VERSION ""

NS_ :

BS_:

BU_: VCU ACU
VAL_TABLE_ AutoCleanSta 1 "On" 0 "Off" ;
VAL_TABLE_ FanSpeedMode 1 "Speed" 0 "Default" ;
VAL_TABLE_ FanModeCtrl 3 "High" 2 "Mid" 1 "Low" 0 "Off" ;
VAL_TABLE_ DedustingCtrl 1 "On" 0 "Off" ;
VAL_TABLE_ ShakerDuster 1 "On" 0 "Off" ;
VAL_TABLE_ SweepUpDwonCtrl 2 "Down" 1 "Up" 0 "No" ;
VAL_TABLE_ MouthpieceUpDownCtrl 2 "Down" 1 "Up" 0 "No" ;
VAL_TABLE_ StartStop 3 "No" 2 "Stop" 1 "Start" 0 "No" ;
VAL_TABLE_ MowingSpeedModeCtrl 3 "High" 2 "Mid" 1 "Low" 0 "Off" ;
VAL_TABLE_ MowingSpeedMode 3 "High" 2 "Mid" 1 "Low" 0 "Off" ;
VAL_TABLE_ SweepModeFb 3 "High" 2 "Mid" 1 "Low" 0 "Off" ;
VAL_TABLE_ SweepModeCtrl 3 "High" 2 "Mid" 1 "Low" 0 "Off" ;
VAL_TABLE_ CarWorkStaFb 7 "crash" 6 "error" 5 "E-stop" 4 "work" 3 "3" 2 "2" 1 "1" 0 "init" ;
VAL_TABLE_ AutoProfessional 1 "Enable" 0 "Disable" ;
VAL_TABLE_ CarWork_State 3 "FAULT" 2 "OK" 1 "SELF_CHECK" 0 "INIT" ;
VAL_TABLE_ CarPower_State 2 "READY" 1 "ON" 0 "OFF" ;
VAL_TABLE_ Headlight 1 "On" 0 "Off" ;
VAL_TABLE_ AEB_Trigger_State 8 "RightTrigger" 4 "LeftTrigger" 2 "BackTrigger" 1 "FrontTrigger" 0 "NoTrigger" ;
VAL_TABLE_ Brake_Light_Actual 1 "BrakeLight_ON" 0 "BrakeLight_OFF" ;
VAL_TABLE_ Turn_Light_Actual 3 "Hazard_Warning_Lampsts_ON" 2 "Right_Turnlampsts_ON" 1 "Left_Turnlampsts_ON" 0 "Turnlampsts_OFF" ;
VAL_TABLE_ VIN_Req 1 "Vin_req_enable" 0 "Vin_req_disable" ;
VAL_TABLE_ Drive_Mode_STS 1 "Speed Drive Mode" 0 "Throttle Paddle Drive Mode" ;
VAL_TABLE_ Steer_Mode_STS 2 "Sync Direction Steer Mode" 1 "Non Direction Steer Mode" 0 "Standard Steer Mode" ;
VAL_TABLE_ Steer_Mode_CTRL 2 "Sync Direction Steer" 1 "Non Direction Steer" 0 "Standard Steer" ;
VAL_TABLE_ Drive_Mode_CTRL 1 "Speed Drive" 0 "Throttle Paddle Drive" ;
VAL_TABLE_ AEB_EN_CTRL 1 "Enable AEB" 0 "Disable AEB" ;
VAL_TABLE_ Vehicle_Mode_State 3 "Standby Mode" 2 "Emergency Mode" 1 "Auto Mode" 0 "Manual Remote  Mode" ;
VAL_TABLE_ BackCrash_State 1 "Crash Event" 0 "No Event" ;
VAL_TABLE_ FrontCrash_State 1 "Crash Event" 0 "No Event" ;
VAL_TABLE_ AEB_State 1 "Active" 0 "Inctive" ;
VAL_TABLE_ Brake_FLT2 1 "Brake system comunication fault" 0 "No fault " ;
VAL_TABLE_ Brake_FLT1 1 "Brake system hardware fault" 0 "No fault" ;
VAL_TABLE_ Brake_EN_CTRL 1 "Enable" 0 "Disable" ;
VAL_TABLE_ Brake_EN_state 3 "Standby" 2 "Takeover" 1 "Auto" 0 "Manual" ;
VAL_TABLE_ Park_FLT 1 "Fault" 0 "No Fault" ;
VAL_TABLE_ Parking_actual 1 "Parking_trigger" 0 "Release" ;
VAL_TABLE_ Park_Target 1 "Parking_trigger" 0 "Release" ;
VAL_TABLE_ Park_EN_CTRL 1 "Enable" 0 "Disable" ;
VAL_TABLE_ Gear_FLT 1 "Fault" 0 "No Fault" ;
VAL_TABLE_ Gear_Actual 4 "D" 3 "N" 2 "R" 1 "P" 0 "Invaild" ;
VAL_TABLE_ Gear_Target 4 "D" 3 "N" 2 "R" 1 "P" 0 "Invalid" ;
VAL_TABLE_ Gear_EN_CTRL 1 "Enable" 0 "Disable" ;
VAL_TABLE_ Throttle_EN_state 3 "Standby" 2 "Takeover" 1 "Auto" 0 "Manual" ;
VAL_TABLE_ Throttle_EN_CTRL 1 "Enable" 0 "Disable" ;
VAL_TABLE_ Steer_EN_state 3 "Standby" 2 "Takeover" 1 "Auto" 0 "Manual" ;
VAL_TABLE_ Steer_EN_CTRL 1 "Enable" 0 "Disable" ;
VAL_TABLE_ Throttle_FLT2 1 "Drive system comunication fault" 0 "No fault" ;
VAL_TABLE_ Throttle_FLT1 1 "Drive system hardware fault" 0 "No fault" ;
VAL_TABLE_ Steer_FLT2 1 "Steer system comunication fault" 0 "No fault" ;
VAL_TABLE_ Steer_FLT1 1 "Steer system hardware fault" 0 "No fault" ;

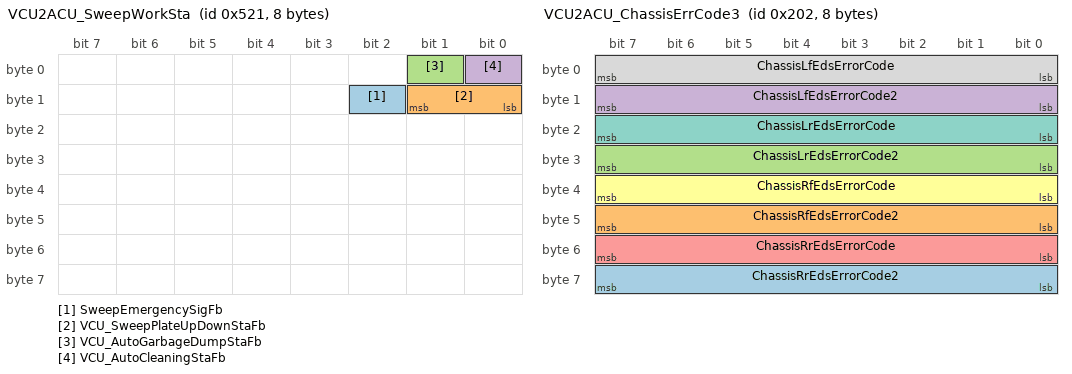
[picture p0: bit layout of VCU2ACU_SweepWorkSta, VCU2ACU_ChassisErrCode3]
BO_ 1313 VCU2ACU_SweepWorkSta: 8 VCU
 SG_ SweepEmergencySigFb : 10|1@0+ (1,0) [0|1] "" Vector__XXX
 SG_ VCU_SweepPlateUpDownStaFb : 9|2@0+ (1,0) [0|1] "" Vector__XXX
 SG_ VCU_AutoGarbageDumpStaFb : 1|1@0+ (1,0) [0|0] "" Vector__XXX
 SG_ VCU_AutoCleaningStaFb : 0|1@0+ (1,0) [0|0] "" Vector__XXX

BO_ 514 VCU2ACU_ChassisErrCode3: 8 VCU
 SG_ ChassisRrEdsErrorCode2 : 63|8@0+ (1,0) [0|0] "" Vector__XXX
 SG_ ChassisRfEdsErrorCode2 : 47|8@0+ (1,0) [0|0] "" Vector__XXX
 SG_ ChassisLrEdsErrorCode2 : 31|8@0+ (1,0) [0|0] "" Vector__XXX
 SG_ ChassisLfEdsErrorCode2 : 15|8@0+ (1,0) [0|0] "" Vector__XXX
 SG_ ChassisRrEdsErrorCode : 55|8@0+ (1,0) [0|0] "" Vector__XXX
 SG_ ChassisRfEdsErrorCode : 39|8@0+ (1,0) [0|0] "" Vector__XXX
 SG_ ChassisLrEdsErrorCode : 23|8@0+ (1,0) [0|0] "" Vector__XXX
 SG_ ChassisLfEdsErrorCode : 7|8@0+ (1,0) [0|0] "" Vector__XXX

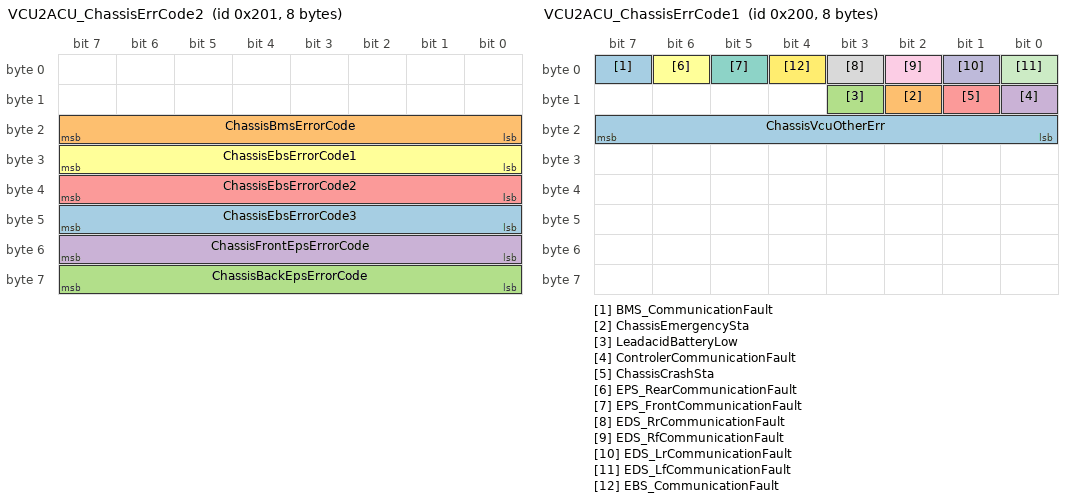
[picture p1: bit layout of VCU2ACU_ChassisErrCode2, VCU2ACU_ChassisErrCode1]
BO_ 513 VCU2ACU_ChassisErrCode2: 8 VCU
 SG_ ChassisEbsErrorCode3 : 47|8@0+ (1,0) [0|0] "" Vector__XXX
 SG_ ChassisBmsErrorCode : 23|8@0+ (1,0) [0|0] "" Vector__XXX
 SG_ ChassisBackEpsErrorCode : 63|8@0+ (1,0) [0|0] "" Vector__XXX
 SG_ ChassisFrontEpsErrorCode : 55|8@0+ (1,0) [0|0] "" Vector__XXX
 SG_ ChassisEbsErrorCode2 : 39|8@0+ (1,0) [0|0] "" Vector__XXX
 SG_ ChassisEbsErrorCode1 : 31|8@0+ (1,0) [0|0] "" Vector__XXX

BO_ 512 VCU2ACU_ChassisErrCode1: 8 VCU
 SG_ BMS_CommunicationFault : 7|1@0+ (1,0) [0|0] "" Vector__XXX
 SG_ ChassisEmergencySta : 10|1@0+ (1,0) [0|0] "" Vector__XXX
 SG_ LeadacidBatteryLow : 11|1@0+ (1,0) [0|0] "" Vector__XXX
 SG_ ControlerCommunicationFault : 8|1@0+ (1,0) [0|0] "" Vector__XXX
 SG_ ChassisCrashSta : 9|1@0+ (1,0) [0|0] "" Vector__XXX
 SG_ EPS_RearCommunicationFault : 6|1@0+ (1,0) [0|0] "" Vector__XXX
 SG_ EPS_FrontCommunicationFault : 5|1@0+ (1,0) [0|0] "" Vector__XXX
 SG_ EDS_RrCommunicationFault : 3|1@0+ (1,0) [0|0] "" Vector__XXX
 SG_ EDS_RfCommunicationFault : 2|1@0+ (1,0) [0|0] "" Vector__XXX
 SG_ EDS_LrCommunicationFault : 1|1@0+ (1,0) [0|0] "" Vector__XXX
 SG_ EDS_LfCommunicationFault : 0|1@0+ (1,0) [0|0] "" Vector__XXX
 SG_ EBS_CommunicationFault : 4|1@0+ (1,0) [0|0] "" Vector__XXX
 SG_ ChassisVcuOtherErr : 23|8@0+ (1,0) [0|0] "" Vector__XXX

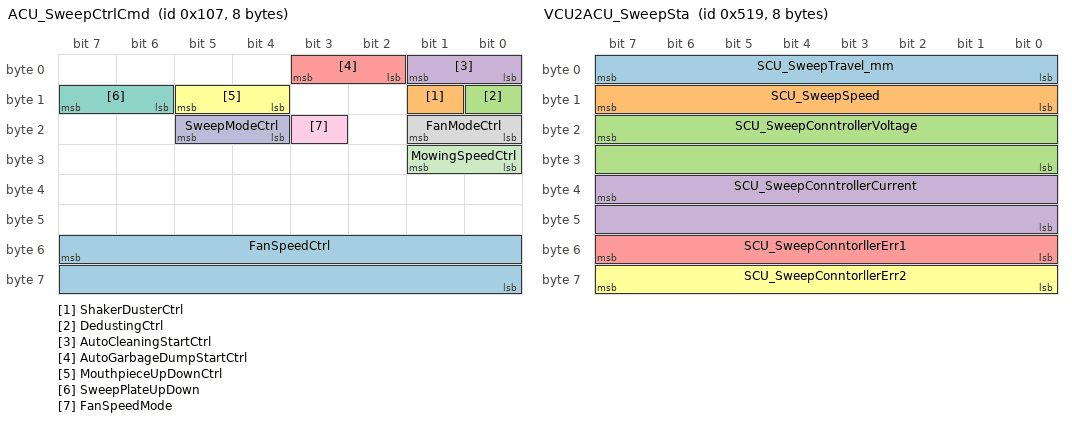
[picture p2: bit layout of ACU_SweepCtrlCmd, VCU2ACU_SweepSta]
BO_ 263 ACU_SweepCtrlCmd: 8 ACU
 SG_ FanSpeedCtrl : 55|16@0+ (1,0) [0|0] "rpm" Vector__XXX
 SG_ ShakerDusterCtrl : 9|1@0+ (1,0) [0|1] "" Vector__XXX
 SG_ DedustingCtrl : 8|1@0+ (1,0) [0|1] "" Vector__XXX
 SG_ AutoCleaningStartCtrl : 1|2@0+ (1,0) [0|3] "" Vector__XXX
 SG_ AutoGarbageDumpStartCtrl : 3|2@0+ (1,0) [0|3] "" Vector__XXX
 SG_ MouthpieceUpDownCtrl : 13|2@0+ (1,0) [0|3] "" Vector__XXX
 SG_ SweepPlateUpDown : 15|2@0+ (1,0) [0|3] "" Vector__XXX
 SG_ FanModeCtrl : 17|2@0+ (1,0) [0|3] "" Vector__XXX
 SG_ FanSpeedMode : 19|1@0+ (1,0) [0|1] "" Vector__XXX
 SG_ SweepModeCtrl : 21|2@0+ (1,0) [0|3] "" Vector__XXX
 SG_ MowingSpeedCtrl : 25|2@0+ (1,0) [0|3] "" Vector__XXX

BO_ 1312 VCU2ACU_SweepWeedingSta: 8 VCU
 SG_ SCU_WeedingSta : 7|8@0+ (1,0) [0|1] "" Vector__XXX

BO_ 1305 VCU2ACU_SweepSta: 8 VCU
 SG_ SCU_SweepTravel_mm : 7|8@0+ (1,0) [0|255] "mm" Vector__XXX
 SG_ SCU_SweepSpeed : 15|8@0+ (1,0) [0|255] "rpm" Vector__XXX
 SG_ SCU_SweepConntrollerVoltage : 23|16@0+ (1,0) [0|1] "" Vector__XXX
 SG_ SCU_SweepConntrollerCurrent : 39|16@0+ (1,0) [0|1] "" Vector__XXX
 SG_ SCU_SweepConntorllerErr1 : 55|8@0+ (1,0) [0|1] "" Vector__XXX
 SG_ SCU_SweepConntorllerErr2 : 63|8@0+ (1,0) [0|1] "" Vector__XXX

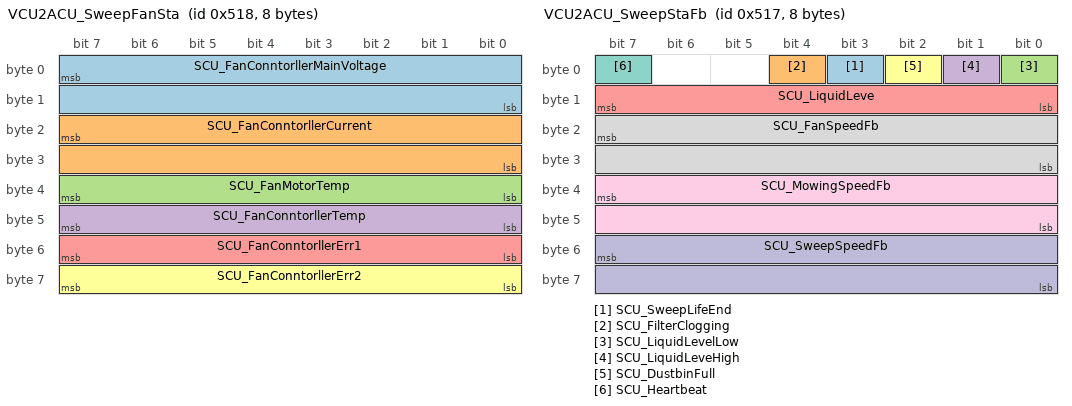
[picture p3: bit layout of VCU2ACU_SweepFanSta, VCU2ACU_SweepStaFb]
BO_ 1304 VCU2ACU_SweepFanSta: 8 VCU
 SG_ SCU_FanConntorllerMainVoltage : 7|16@0+ (1,0) [0|500] "V" Vector__XXX
 SG_ SCU_FanConntorllerCurrent : 23|16@0+ (1,-2000) [-2000|2000] "A" Vector__XXX
 SG_ SCU_FanMotorTemp : 39|8@0+ (1,-40) [-40|210] "℃" Vector__XXX
 SG_ SCU_FanConntorllerTemp : 47|8@0+ (1,-40) [-40|160] "℃" Vector__XXX
 SG_ SCU_FanConntorllerErr1 : 55|8@0+ (1,0) [0|1] "" Vector__XXX
 SG_ SCU_FanConntorllerErr2 : 63|8@0+ (1,0) [0|1] "" Vector__XXX

BO_ 1303 VCU2ACU_SweepStaFb: 8 VCU
 SG_ SCU_SweepLifeEnd : 3|1@0+ (1,0) [0|0] "" Vector__XXX
 SG_ SCU_FilterClogging : 4|1@0+ (1,0) [0|0] "" Vector__XXX
 SG_ SCU_LiquidLevelLow : 0|1@0+ (1,0) [0|1] "" Vector__XXX
 SG_ SCU_LiquidLeveHigh : 1|1@0+ (1,0) [0|1] "" Vector__XXX
 SG_ SCU_LiquidLeve : 15|8@0+ (1,0) [0|1] "" Vector__XXX
 SG_ SCU_DustbinFull : 2|1@0+ (1,0) [0|1] "" Vector__XXX
 SG_ SCU_Heartbeat : 7|1@0+ (1,0) [0|1] "" Vector__XXX
 SG_ SCU_FanSpeedFb : 23|16@0+ (1,0) [0|1] "" Vector__XXX
 SG_ SCU_MowingSpeedFb : 39|16@0+ (1,0) [0|1] "" Vector__XXX
 SG_ SCU_SweepSpeedFb : 55|16@0+ (1,0) [0|1] "" Vector__XXX

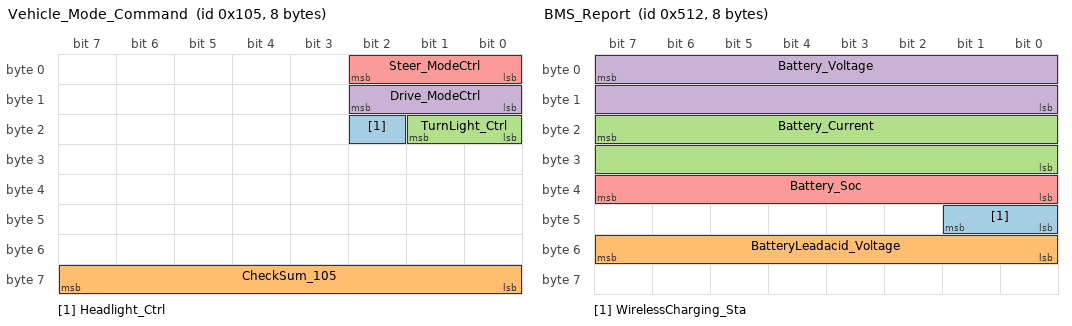
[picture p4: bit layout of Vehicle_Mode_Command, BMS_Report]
BO_ 261 Vehicle_Mode_Command: 8 ACU
 SG_ Headlight_Ctrl : 18|1@0+ (1,0) [0|0] "" Vector__XXX
 SG_ CheckSum_105 : 63|8@0+ (1,0) [0|255] "" Vector__XXX
 SG_ TurnLight_Ctrl : 17|2@0+ (1,0) [0|7] "" Vector__XXX
 SG_ Drive_ModeCtrl : 10|3@0+ (1,0) [0|7] "" Vector__XXX
 SG_ Steer_ModeCtrl : 2|3@0+ (1,0) [0|7] "" Vector__XXX

BO_ 1298 BMS_Report: 8 VCU
 SG_ WirelessCharging_Sta : 41|2@0+ (1,0) [0|0] "" Vector__XXX
 SG_ BatteryLeadacid_Voltage : 55|8@0+ (0.1,0) [0|0] "V" Vector__XXX
 SG_ Battery_Current : 23|16@0+ (0.1,-3200) [-3200|3353.5] "A" Vector__XXX
 SG_ Battery_Voltage : 7|16@0+ (0.01,0) [0|300] "V" Vector__XXX
 SG_ Battery_Soc : 39|8@0+ (1,0) [0|100] "%" Vector__XXX

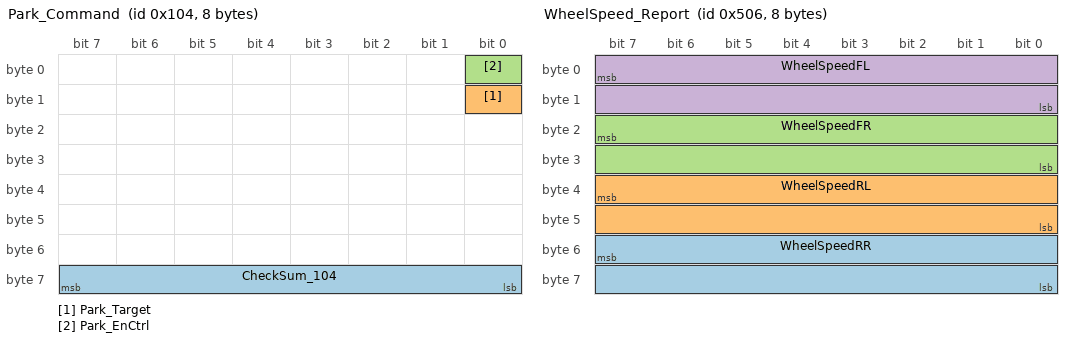
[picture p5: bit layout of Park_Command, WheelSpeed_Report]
BO_ 260 Park_Command: 8 ACU
 SG_ CheckSum_104 : 63|8@0+ (1,0) [0|255] "" Vector__XXX
 SG_ Park_Target : 8|1@0+ (1,0) [0|1] "" Vector__XXX
 SG_ Park_EnCtrl : 0|1@0+ (1,0) [0|1] "" Vector__XXX

BO_ 1286 WheelSpeed_Report: 8 VCU
 SG_ WheelSpeedRR : 55|16@0+ (0.001,0) [0|65.535] "m/s"  ACU
 SG_ WheelSpeedRL : 39|16@0+ (0.001,0) [0|65.535] "m/s"  ACU
 SG_ WheelSpeedFR : 23|16@0+ (0.001,0) [0|65.535] "m/s"  ACU
 SG_ WheelSpeedFL : 7|16@0+ (0.001,0) [0|65.535] "m/s"  ACU

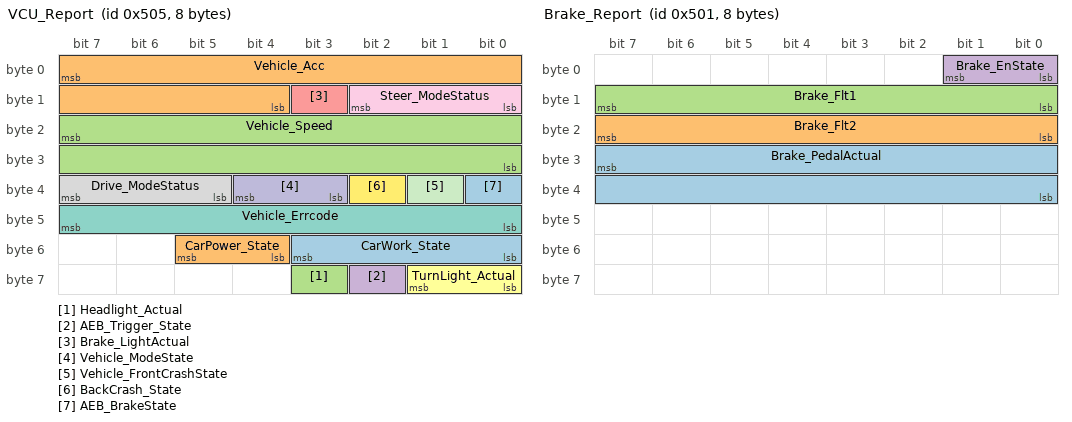
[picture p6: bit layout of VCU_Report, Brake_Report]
BO_ 1285 VCU_Report: 8 VCU
 SG_ CarWork_State : 51|4@0+ (1,0) [0|0] "" Vector__XXX
 SG_ CarPower_State : 53|2@0+ (1,0) [0|0] "" Vector__XXX
 SG_ Headlight_Actual : 59|1@0+ (1,0) [0|0] "" Vector__XXX
 SG_ AEB_Trigger_State : 58|1@0+ (1,0) [0|1] "" Vector__XXX
 SG_ Brake_LightActual : 11|1@0+ (1,0) [0|1] "" Vector__XXX
 SG_ TurnLight_Actual : 57|2@0+ (1,0) [0|0] "" Vector__XXX
 SG_ Vehicle_Errcode : 47|8@0+ (1,0) [0|255] "" Vector__XXX
 SG_ Drive_ModeStatus : 39|3@0+ (1,0) [0|7] "" Vector__XXX
 SG_ Steer_ModeStatus : 10|3@0+ (1,0) [0|7] "" Vector__XXX
 SG_ Vehicle_ModeState : 36|2@0+ (1,0) [0|0] "" Vector__XXX
 SG_ Vehicle_FrontCrashState : 33|1@0+ (1,0) [0|0] "" Vector__XXX
 SG_ BackCrash_State : 34|1@0+ (1,0) [0|0] "" Vector__XXX
 SG_ AEB_BrakeState : 32|1@0+ (1,0) [0|0] "" Vector__XXX
 SG_ Vehicle_Acc : 7|12@0- (0.01,0) [-10|10] "m/s^2"  ACU
 SG_ Vehicle_Speed : 23|16@0- (0.001,0) [-32.768|32.767] "m/s"  ACU

BO_ 1284 Park_Report: 8 VCU
 SG_ Parking_Actual : 0|1@0+ (1,0) [0|1] ""  ACU
 SG_ Park_Flt : 15|8@0+ (1,0) [0|1] ""  ACU

BO_ 1283 Gear_Report: 8 VCU
 SG_ Gear_Flt : 15|8@0+ (1,0) [0|1] ""  ACU
 SG_ Gear_Actual : 2|3@0+ (1,0) [0|4] ""  ACU

BO_ 1281 Brake_Report: 8 VCU
 SG_ Brake_PedalActual : 31|16@0+ (0.1,0) [0|100] "%"  ACU
 SG_ Brake_Flt2 : 23|8@0+ (1,0) [0|1] ""  ACU
 SG_ Brake_Flt1 : 15|8@0+ (1,0) [0|1] ""  ACU
 SG_ Brake_EnState : 1|2@0+ (1,0) [0|2] ""  ACU

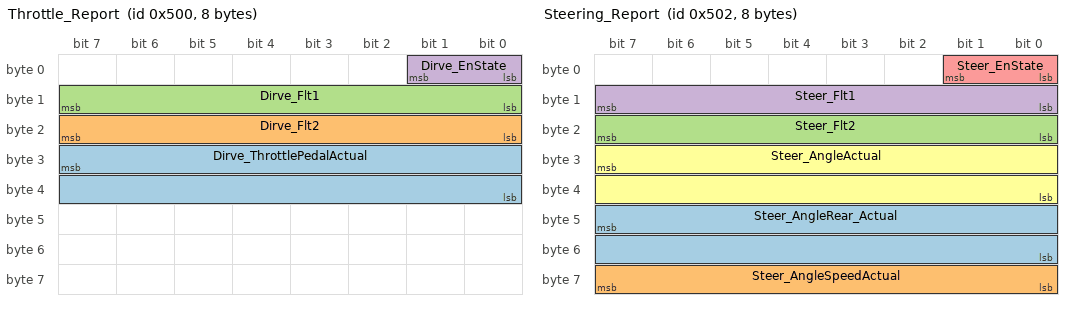
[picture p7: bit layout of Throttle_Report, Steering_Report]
BO_ 1280 Throttle_Report: 8 VCU
 SG_ Dirve_ThrottlePedalActual : 31|16@0+ (0.1,0) [0|100] "%"  ACU
 SG_ Dirve_Flt2 : 23|8@0+ (1,0) [0|1] ""  ACU
 SG_ Dirve_Flt1 : 15|8@0+ (1,0) [0|1] ""  ACU
 SG_ Dirve_EnState : 1|2@0+ (1,0) [0|2] ""  ACU

BO_ 1282 Steering_Report: 8 VCU
 SG_ Steer_AngleRear_Actual : 47|16@0+ (1,-500) [-500|500] "deg" Vector__XXX
 SG_ Steer_AngleSpeedActual : 63|8@0+ (1,0) [0|250] "deg/s"  ACU
 SG_ Steer_Flt2 : 23|8@0+ (1,0) [0|255] ""  ACU
 SG_ Steer_Flt1 : 15|8@0+ (1,0) [0|255] ""  ACU
 SG_ Steer_EnState : 1|2@0+ (1,0) [0|2] ""  ACU
 SG_ Steer_AngleActual : 31|16@0+ (1,-500) [-500|500] "deg"  ACU

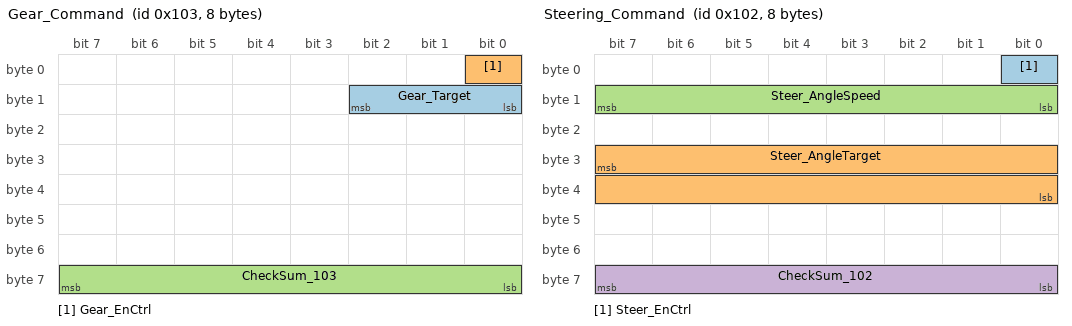
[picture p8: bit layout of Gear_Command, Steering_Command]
BO_ 259 Gear_Command: 8 ACU
 SG_ Gear_Target : 10|3@0+ (1,0) [0|4] "" Vector__XXX
 SG_ Gear_EnCtrl : 0|1@0+ (1,0) [0|1] "" Vector__XXX
 SG_ CheckSum_103 : 63|8@0+ (1,0) [0|255] "" Vector__XXX

BO_ 258 Steering_Command: 8 ACU
 SG_ Steer_EnCtrl : 0|1@0+ (1,0) [0|1] "" Vector__XXX
 SG_ Steer_AngleTarget : 31|16@0+ (1,-500) [-500|500] "deg" Vector__XXX
 SG_ Steer_AngleSpeed : 15|8@0+ (1,0) [0|250] "deg/s" Vector__XXX
 SG_ CheckSum_102 : 63|8@0+ (1,0) [0|255] "" Vector__XXX

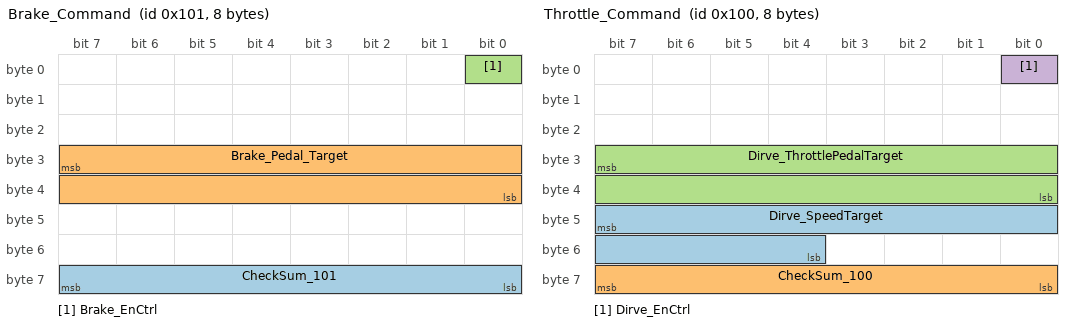
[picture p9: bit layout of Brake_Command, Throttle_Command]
BO_ 257 Brake_Command: 8 ACU
 SG_ CheckSum_101 : 63|8@0+ (1,0) [0|255] "" Vector__XXX
 SG_ Brake_Pedal_Target : 31|16@0+ (0.1,0) [0|100] "%" Vector__XXX
 SG_ Brake_EnCtrl : 0|1@0+ (1,0) [0|1] "" Vector__XXX

BO_ 256 Throttle_Command: 8 ACU
 SG_ Dirve_SpeedTarget : 47|12@0+ (0.01,0) [0|40.95] "m/s" Vector__XXX
 SG_ CheckSum_100 : 63|8@0+ (1,0) [0|255] "" Vector__XXX
 SG_ Dirve_ThrottlePedalTarget : 31|16@0+ (0.1,0) [0|100] "%" Vector__XXX
 SG_ Dirve_EnCtrl : 0|1@0+ (1,0) [0|1] "" Vector__XXX

CM_ "V1.0";
CM_ BO_ 1313 "需要传到云平台";
CM_ SG_ 1313 SweepEmergencySigFb "清扫系统紧急停止反馈";
CM_ SG_ 1313 VCU_SweepPlateUpDownStaFb "扫盘升降状态反馈";
CM_ SG_ 1313 VCU_AutoGarbageDumpStaFb "一键倾倒状态反馈";
CM_ SG_ 1313 VCU_AutoCleaningStaFb "一键清扫状态反馈";
CM_ BO_ 514 "需要传到云平台";
CM_ BO_ 513 "需要传到云平台";
CM_ BO_ 512 "需要传到云平台";
CM_ BO_ 263 "自动驾驶通过VCU控制清扫系统";
CM_ SG_ 263 FanSpeedCtrl "风机速度控制";
CM_ SG_ 263 DedustingCtrl "喷雾降尘";
CM_ SG_ 263 AutoCleaningStartCtrl "一键清扫控制";
CM_ SG_ 263 AutoGarbageDumpStartCtrl "一键倾倒";
CM_ SG_ 263 MouthpieceUpDownCtrl "吸盘升降控制";
CM_ SG_ 263 SweepPlateUpDown "扫盘升降";
CM_ SG_ 263 FanModeCtrl "风机工作模式";
CM_ SG_ 263 FanSpeedMode "风机速度模式";
CM_ SG_ 263 SweepModeCtrl "扫盘转速挡位控制";
CM_ SG_ 263 MowingSpeedCtrl "割草转速挡位控制";
CM_ BO_ 1312 "需要传到云平台";
CM_ BO_ 1305 "需要传到云平台";
CM_ BO_ 1304 "需要传到云平台";
CM_ BO_ 1303 "需要传到云平台";
CM_ SG_ 1298 Battery_Current "Battery Total Current";
CM_ SG_ 1298 Battery_Voltage "Battery Total Voltage";
CM_ SG_ 1298 Battery_Soc "Battery Soc percentage";
CM_ SG_ 1281 Brake_Flt2 "Brake system communication fault";
CM_ SG_ 1281 Brake_Flt1 "Brake system hardware fault";
CM_ SG_ 1280 Dirve_Flt2 "Drive system communication fault";
CM_ SG_ 1280 Dirve_Flt1 "Drive system hardware fault";
CM_ SG_ 1282 Steer_Flt2 "Steer system communication fault";
CM_ SG_ 1282 Steer_Flt1 "Steer system hardware fault";
BA_DEF_  "BusType" STRING ;
BA_DEF_  "GenNWMApBusSleep" STRING ;
BA_DEF_  "GenNWMApCanNormal" STRING ;
BA_DEF_  "GenNWMApCanOff" STRING ;
BA_DEF_  "GenNWMApCanOn" STRING ;
BA_DEF_  "GenNWMApCanSleep" STRING ;
BA_DEF_  "GenNWMApCanWakeUp" STRING ;
BA_DEF_  "GenNWMGotoMode_Awake" STRING ;
BA_DEF_  "GenNWMGotoMode_BusSleep" STRING ;
BA_DEF_  "GenNWMTalkNM" STRING ;
BA_DEF_ BU_  "NodeLayerModules" STRING ;
BA_DEF_ BO_  "GenMsgCycleTime" INT 2 50000;
BA_DEF_ BO_  "GenMsgDelayTime" INT 1 1000;
BA_DEF_ BO_  "GenMsgNrOfRepetitions" INT 1 999999;
BA_DEF_ SG_  "GenSigStartValue" FLOAT 0 100000000000;
BA_DEF_  "GenEnvVarEndingDsp" STRING ;
BA_DEF_  "GenEnvVarEndingSnd" STRING ;
BA_DEF_  "GenEnvVarPrefix" STRING ;
BA_DEF_ SG_  "GenSigEnvVarType" ENUM  "int","float","undef";
BA_DEF_DEF_  "BusType" "CAN";
BA_DEF_DEF_  "GenNWMApBusSleep" "apBusSleep()";
BA_DEF_DEF_  "GenNWMApCanNormal" "apCanNormal()";
BA_DEF_DEF_  "GenNWMApCanOff" "apCanOff()";
BA_DEF_DEF_  "GenNWMApCanOn" "apCanOn()";
BA_DEF_DEF_  "GenNWMApCanSleep" "apCanSleep()";
BA_DEF_DEF_  "GenNWMApCanWakeUp" "apCanWakeUp()";
BA_DEF_DEF_  "GenNWMGotoMode_Awake" "GotoMode_Awake()";
BA_DEF_DEF_  "GenNWMGotoMode_BusSleep" "GotoMode_BusSleep()";
BA_DEF_DEF_  "GenNWMTalkNM" "TalkNM()";
BA_DEF_DEF_  "NodeLayerModules" "CANoeILNLVector.dll";
BA_DEF_DEF_  "GenMsgCycleTime" 100;
BA_DEF_DEF_  "GenMsgDelayTime" 1;
BA_DEF_DEF_  "GenMsgNrOfRepetitions" 1;
BA_DEF_DEF_  "GenSigStartValue" 0;
BA_DEF_DEF_  "GenEnvVarEndingDsp" "Dsp_";
BA_DEF_DEF_  "GenEnvVarEndingSnd" "_";
BA_DEF_DEF_  "GenEnvVarPrefix" "Env";
BA_DEF_DEF_  "GenSigEnvVarType" "undef";
BA_ "GenMsgCycleTime" BO_ 514 200;
BA_ "GenMsgCycleTime" BO_ 513 200;
BA_ "GenMsgCycleTime" BO_ 512 200;
BA_ "GenMsgCycleTime" BO_ 1298 20;
BA_ "GenMsgCycleTime" BO_ 260 20;
BA_ "GenMsgCycleTime" BO_ 1286 20;
BA_ "GenMsgCycleTime" BO_ 1285 20;
BA_ "GenMsgCycleTime" BO_ 1284 50;
BA_ "GenMsgCycleTime" BO_ 1283 50;
BA_ "GenMsgCycleTime" BO_ 1281 20;
BA_ "GenMsgCycleTime" BO_ 1280 20;
BA_ "GenMsgCycleTime" BO_ 1282 20;
BA_ "GenMsgCycleTime" BO_ 259 50;
BA_ "GenMsgCycleTime" BO_ 258 20;
BA_ "GenMsgCycleTime" BO_ 257 20;
BA_ "GenMsgCycleTime" BO_ 256 20;
BA_ "GenSigStartValue" SG_ 1298 Battery_Current 32000;
BA_ "GenSigStartValue" SG_ 1282 Steer_AngleRear_Actual 500;
BA_ "GenSigStartValue" SG_ 1282 Steer_AngleActual 500;
BA_ "GenSigStartValue" SG_ 258 Steer_AngleTarget 500;
VAL_ 1313 VCU_SweepPlateUpDownStaFb 2 "Down" 1 "Up" 0 "No" ;
VAL_ 1313 VCU_AutoGarbageDumpStaFb 1 "On" 0 "Off" ;
VAL_ 1313 VCU_AutoCleaningStaFb 1 "On" 0 "Off" ;
VAL_ 263 ShakerDusterCtrl 1 "On" 0 "Off" ;
VAL_ 263 DedustingCtrl 1 "On" 0 "Off" ;
VAL_ 263 AutoCleaningStartCtrl 3 "No" 2 "Stop" 1 "Start" 0 "No" ;
VAL_ 263 AutoGarbageDumpStartCtrl 3 "No" 2 "Stop" 1 "Start" 0 "No" ;
VAL_ 263 MouthpieceUpDownCtrl 2 "Down" 1 "Up" 0 "No" ;
VAL_ 263 SweepPlateUpDown 2 "Down" 1 "Up" 0 "No" ;
VAL_ 263 FanModeCtrl 3 "High" 2 "Mid" 1 "Low" 0 "Off" ;
VAL_ 263 FanSpeedMode 1 "Speed" 0 "Default" ;
VAL_ 263 SweepModeCtrl 3 "High" 2 "Mid" 1 "Low" 0 "Off" ;
VAL_ 263 MowingSpeedCtrl 3 "High" 2 "Mid" 1 "Low" 0 "Off" ;
VAL_ 261 Headlight_Ctrl 1 "On" 0 "Off" ;
VAL_ 261 TurnLight_Ctrl 3 "Hazard_Warning_Lampsts_ON" 2 "Right_Turnlamp_ON" 1 "Left_Turnlamp_ON" 0 "Turnlamp_OFF" ;
VAL_ 261 Drive_ModeCtrl 1 "Speed Drive" 0 "Throttle Paddle Drive" ;
VAL_ 261 Steer_ModeCtrl 2 "Sync Direction Steer" 1 "Non Direction Steer" 0 "Standard Steer" ;
VAL_ 260 Park_Target 1 "Parking_trigger" 0 "Release" ;
VAL_ 260 Park_EnCtrl 1 "Enable" 0 "Disable" ;
VAL_ 1285 CarWork_State 7 "crash" 6 "error" 5 "E-stop" 4 "work" 3 "3" 2 "2" 1 "1" 0 "init" ;
VAL_ 1285 CarPower_State 2 "READY" 1 "ON" 0 "OFF" ;
VAL_ 1285 Headlight_Actual 1 "On" 0 "Off" ;
VAL_ 1285 AEB_Trigger_State 8 "RightTrigger" 4 "LeftTrigger" 2 "BackTrigger" 1 "FrontTrigger" 0 "NoTrigger" ;
VAL_ 1285 Brake_LightActual 1 "BrakeLight_ON" 0 "BrakeLight_OFF" ;
VAL_ 1285 TurnLight_Actual 3 "Hazard_Warning_Lampsts_ON" 2 "Right_Turnlampsts_ON" 1 "Left_Turnlampsts_ON" 0 "Turnlampsts_OFF" ;
VAL_ 1285 Drive_ModeStatus 1 "Speed Drive Mode" 0 "Throttle Paddle Drive Mode" ;
VAL_ 1285 Steer_ModeStatus 2 "Sync Direction Steer Mode" 1 "Non Direction Steer Mode" 0 "Standard Steer Mode" ;
VAL_ 1285 Vehicle_ModeState 3 "Standby Mode" 2 "Emergency Mode" 1 "Auto Mode" 0 "Manual Remote Mode" ;
VAL_ 1285 Vehicle_FrontCrashState 1 "Crash Event" 0 "No Event" ;
VAL_ 1285 BackCrash_State 1 "Crash Event" 0 "No Event" ;
VAL_ 1285 AEB_BrakeState 1 "Active" 0 "Inactive" ;
VAL_ 1284 Parking_Actual 1 "Parking_trigger" 0 "Release" ;
VAL_ 1284 Park_Flt 1 "Fault" 0 "No Fault" ;
VAL_ 1283 Gear_Flt 1 "Fault" 0 "No Fault" ;
VAL_ 1283 Gear_Actual 4 "DRIVE" 3 "NEUTRAL" 2 "REVERSE" 1 "PARK" 0 "INVALID" ;
VAL_ 1281 Brake_Flt2 1 "Brake system comunication fault" 0 "No fault " ;
VAL_ 1281 Brake_Flt1 1 "Brake system hardware fault" 0 "No fault" ;
VAL_ 1281 Brake_EnState 3 "Standby" 2 "Takeover" 1 "Auto" 0 "Manual" ;
VAL_ 1280 Dirve_Flt2 1 "Drive system comunication fault" 0 "No fault" ;
VAL_ 1280 Dirve_Flt1 1 "Drive system hardware fault" 0 "No fault" ;
VAL_ 1280 Dirve_EnState 3 "Standby" 2 "Takeover" 1 "Auto" 0 "Manual" ;
VAL_ 1282 Steer_Flt2 1 "Steer system comunication fault" 0 "No fault" ;
VAL_ 1282 Steer_Flt1 1 "Steer system hardware fault" 0 "No fault" ;
VAL_ 1282 Steer_EnState 3 "Standby" 2 "Takeover" 1 "Auto" 0 "Manual" ;
VAL_ 259 Gear_Target 4 "DRIVE" 3 "NEUTRAL" 2 "REVERSE" 1 "PARK" 0 "INVALID" ;
VAL_ 259 Gear_EnCtrl 1 "Enable" 0 "Disable" ;
VAL_ 258 Steer_EnCtrl 1 "Enable" 0 "Disable" ;
VAL_ 257 Brake_EnCtrl 1 "Enable" 0 "Disable" ;
VAL_ 256 Dirve_EnCtrl 1 "Enable" 0 "Disable" ;
